# RE01_256KB register map
Vendor: Renesas Electronics Corporation; Series: RE01; File version: 1.00.01
CPU: CM0PLUS r0p1, little endian, MPU, no FPU, VTOR, 2 interrupt priority bits, 32 interrupts
Registers are 8-bit, read-write, reset 0x0 unless marked. A register's access mark holds for its fields unless they carry their own. Offsets are from the block's base; [hi:lo] are bit positions; {n}, {i} and the like mark numbered series; 'fields as' and 'values as' point back to an identical list.

## PFS — Pmn Pin Function Control Register
Base 0x40040800
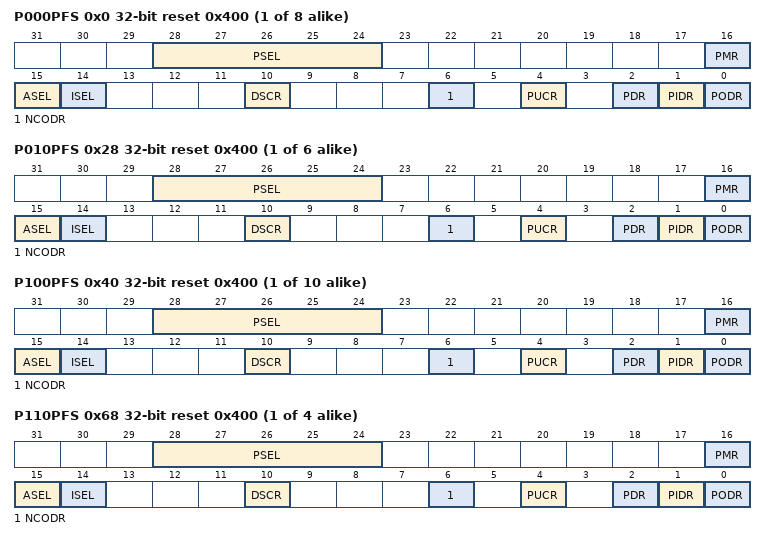
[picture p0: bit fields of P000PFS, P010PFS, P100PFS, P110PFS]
{0x0+4i} P00{i}PFS (i=0..7) 32-bit reset 0x400 (reset mask 0xFFFFFFFD) — Port 00{i} Pin Function Select Register
  [28:24] PSEL — Peripheral Function Select
  [16] PMR — Port Mode Control
    0=Use the pin as a general I/O port; 1=Use the pin as a peripheral module
  [15] ASEL — Analog Input Enable
    0=Do not use as an analog pin; 1=Use as an analog pin
  [14] ISEL — IRQ Input Enable
    0=Do not use as an IRQn input pin; 1=Use as an IRQn input pin
  [10] DSCR — Port Drive Capability
    0=Middle drive; 1=High drive
  [6] NCODR — N-Channel Open-Drain Control
    0=CMOS output; 1=NMOS open-drain output
  [4] PUCR — Pull-Up Control
    0=Disables input pull-up; 1=Enables input pull-up
  [2] PDR — Port Direction
    0=Input (functions as an input pin); 1=Output (functions as an output pin)
  [1] PIDR ro — Port Input Data
    0=Low input; 1=High input
  [0] PODR — Port Output Data
    0=Low output; 1=High output
{0x0+4i} P0{i}PFS (i=10..15) 32-bit reset 0x400 (reset mask 0xFFFFFFFD) — Port 0{i} Pin Function Select Register
  fields as P000PFS
{0x40+4i} P10{i}PFS (i=0..9) 32-bit reset 0x400 (reset mask 0xFFFFFFFD) — Port 10{i} Pin Function Select Register
  fields as P000PFS
{0x40+4i} P1{i}PFS (i=10..13) 32-bit reset 0x400 (reset mask 0xFFFFFFFD) — Port 1{i} Pin Function Select Register
  fields as P000PFS
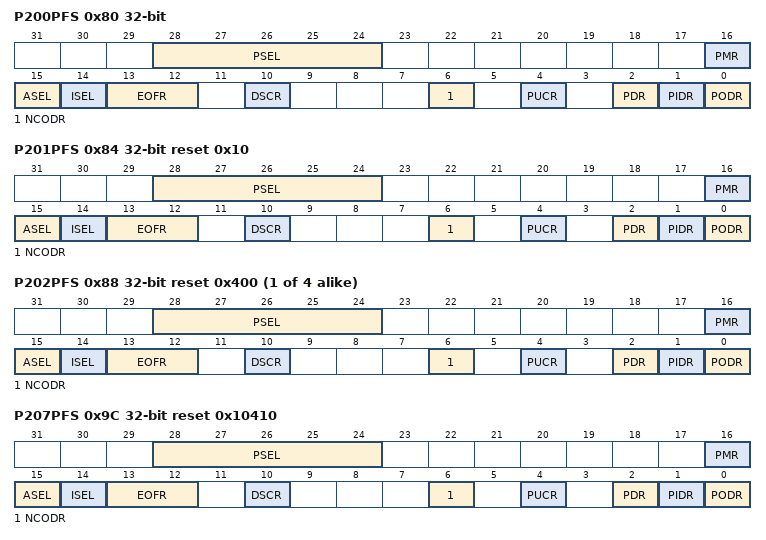
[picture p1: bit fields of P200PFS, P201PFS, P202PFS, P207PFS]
0x80 P200PFS 32-bit (reset mask 0xFFFFFFFD) — Port 200 Pin Function Select Register
  [28:24] PSEL — Peripheral Function Select
  [16] PMR — Port Mode Control
    values as P000PFS.PMR
  [15] ASEL — Analog Input Enable
    0=Do not use as an analog pin; 1=Use as an analog pin
  [14] ISEL — IRQ Input Enable
    values as P000PFS.ISEL
  [13:12] EOFR — Edge detection
    0=Disable edge detection; 1=Detect rising edge; 2=Detect falling edge; 3=Detect both edges
  [10] DSCR — Port Drive Capability
    0=Middle drive; 1=High drive
  [6] NCODR — N-Channel Open-Drain Control
    0=CMOS output; 1=NMOS open-drain output
  [4] PUCR — Pull-Up Control
    0=Disables input pull-up; 1=Enables input pull-up
  [2] PDR — Port Direction
    values as P000PFS.PDR
  [1] PIDR ro — Port Input Data
    0=Low input; 1=High input
  [0] PODR — Port Output Data
    0=Low output; 1=High output
0x84 P201PFS 32-bit reset 0x10 (reset mask 0xFFFFFFFD) — Port 201 Pin Function Select Register
  fields as P200PFS
{0x80+4i} P20{i}PFS (i=2..5) 32-bit reset 0x400 (reset mask 0xFFFFFFFD) — Port 20{i} Pin Function Select Register
  fields as P200PFS
0x9C P207PFS 32-bit reset 0x10410 (reset mask 0xFFFFFFFD) — Port 207 Pin Function Select Register
  fields as P200PFS
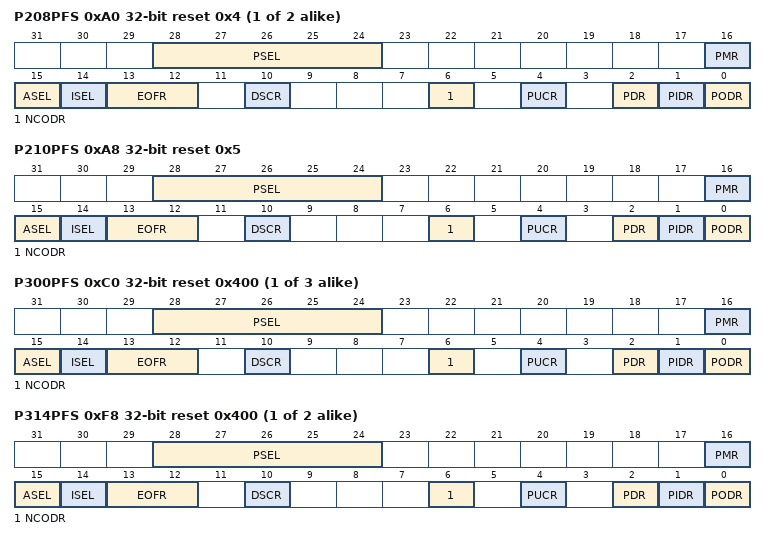
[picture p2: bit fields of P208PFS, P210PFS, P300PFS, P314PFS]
{0x80+4i} P20{i}PFS (i=8..9) 32-bit reset 0x4 (reset mask 0xFFFFFFFD) — Port 20{i} Pin Function Select Register
  fields as P200PFS
0xA8 P210PFS 32-bit reset 0x5 (reset mask 0xFFFFFFFD) — Port 210 Pin Function Select Register
  fields as P200PFS
{0xC0+4i} P30{i}PFS (i=0..2) 32-bit reset 0x400 (reset mask 0xFFFFFFFD) — Port 30{i} Pin Function Select Register
  fields as P200PFS
{0xC0+4i} P3{i}PFS (i=14..15) 32-bit reset 0x400 (reset mask 0xFFFFFFFD) — Port 3{i} Pin Function Select Register
  fields as P200PFS
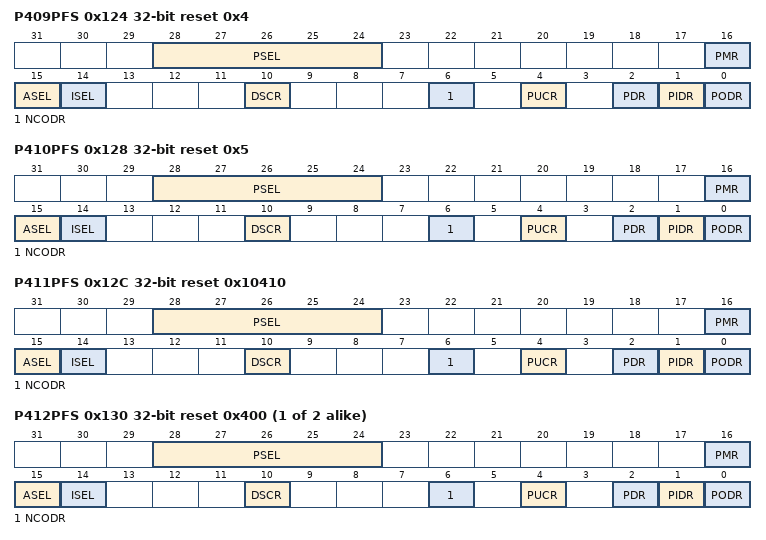
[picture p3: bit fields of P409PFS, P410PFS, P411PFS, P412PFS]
0x124 P409PFS 32-bit reset 0x4 (reset mask 0xFFFFFFFD) — Port 409 Pin Function Select Register
  fields as P000PFS
0x128 P410PFS 32-bit reset 0x5 (reset mask 0xFFFFFFFD) — Port 410 Pin Function Select Register
  fields as P000PFS
0x12C P411PFS 32-bit reset 0x10410 (reset mask 0xFFFFFFFD) — Port 411 Pin Function Select Register
  fields as P000PFS
{0x100+4i} P4{i}PFS (i=12..13) 32-bit reset 0x400 (reset mask 0xFFFFFFFD) — Port 4{i} Pin Function Select Register
  fields as P000PFS
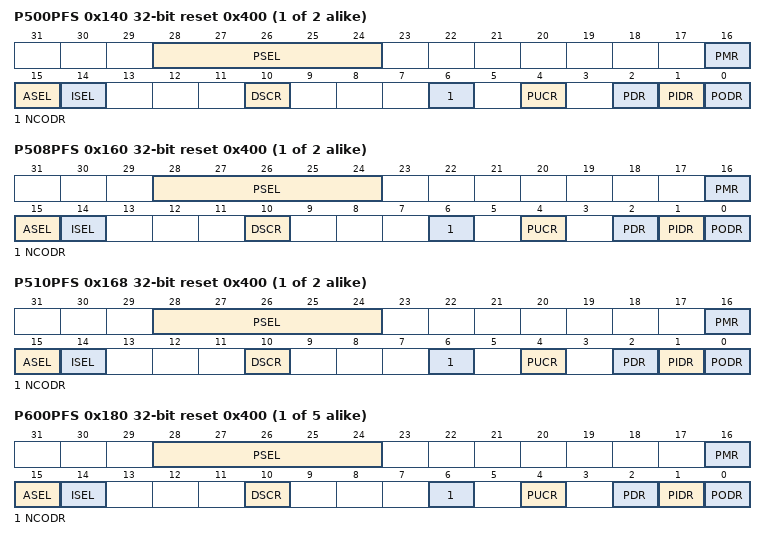
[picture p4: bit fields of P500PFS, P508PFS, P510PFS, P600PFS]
{0x140+4i} P50{i}PFS (i=0..1) 32-bit reset 0x400 (reset mask 0xFFFFFFFD) — Port 50{i}Pin Function Select Register
  fields as P000PFS
{0x140+4i} P50{i}PFS (i=8..9) 32-bit reset 0x400 (reset mask 0xFFFFFFFD) — Port 50{i}Pin Function Select Register
  fields as P000PFS
{0x140+4i} P5{i}PFS (i=10..11) 32-bit reset 0x400 (reset mask 0xFFFFFFFD) — Port 5{i}Pin Function Select Register
  fields as P000PFS
{0x180+4i} P60{i}PFS (i=0..4) 32-bit reset 0x400 (reset mask 0xFFFFFFFD) — Port 60{i} Pin Function Select Register
  fields as P000PFS
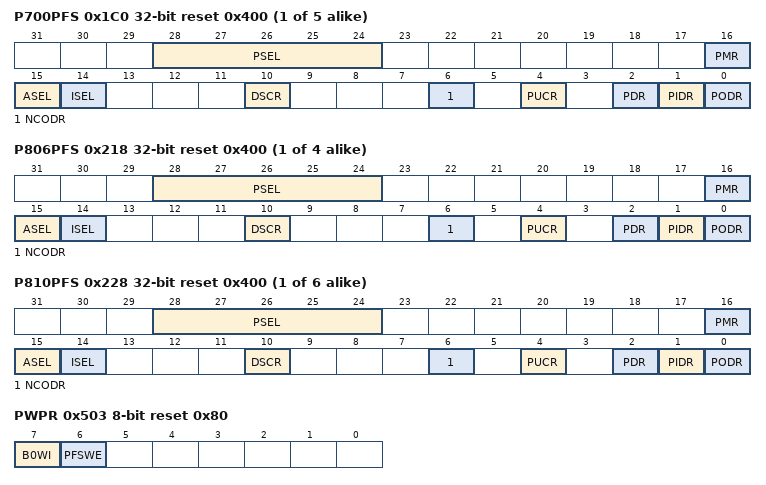
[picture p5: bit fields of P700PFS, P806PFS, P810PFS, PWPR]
{0x1C0+4i} P70{i}PFS (i=0..4) 32-bit reset 0x400 (reset mask 0xFFFFFFFD) — Port 70{i} Pin Function Select Register
  fields as P000PFS
{0x200+4i} P80{i}PFS (i=6..9) 32-bit reset 0x400 (reset mask 0xFFFFFFFD) — Port 80{i} Pin Function Select Register
  fields as P000PFS
{0x200+4i} P8{i}PFS (i=10..15) 32-bit reset 0x400 (reset mask 0xFFFFFFFD) — Port 8{i} Pin Function Select Register
  fields as P000PFS
0x503 PWPR reset 0x80 — Write-Protect Register
  [7] B0WI — PFSWE Bit Write Disable
    0=Writing to the PFSWE bit is enabled; 1=Writing to the PFSWE bit is disabled
  [6] PFSWE — PmnPFS Register Write Enable
    0=Writing to the PmnPFS register is disabled; 1=Writing to the PmnPFS register is enabled
